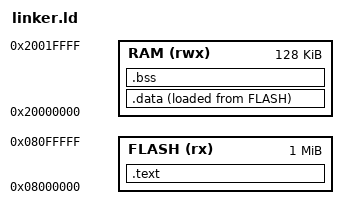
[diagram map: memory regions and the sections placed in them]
ENTRY(Reset_Handler)

MEMORY
{
    FLASH (rx)  : ORIGIN = 0x08000000, LENGTH = 1024K
    RAM   (rwx) : ORIGIN = 0x20000000, LENGTH = 128K
}

_stack_top = ORIGIN(RAM) + LENGTH(RAM);

SECTIONS
{
    .text :
    {
        KEEP(*(.isr_vector))
        *(.text*)
        *(.rodata*)
        . = ALIGN(4);
        _etext = .;
    } > FLASH

    .data :
    {
        . = ALIGN(4);
        _sdata = .;
        *(.data*)
        . = ALIGN(4);
        _edata = .;
    } > RAM AT > FLASH

    _sidata = LOADADDR(.data);

    .bss :
    {
        . = ALIGN(4);
        _sbss = .;
        *(.bss*)
        *(COMMON)
        . = ALIGN(4);
        _ebss = .;
    } > RAM

    _end = .;
}
